# ATmega32C1 device description
Architecture: AVR8; Family: megaAVR
Registers are 8-bit, access not given, no defined reset value unless marked. A register's access mark holds for its fields unless they carry their own. Offsets are from the block's base; [hi:lo] are bit positions; {n}, {i} and the like mark numbered series.

## CPU — CPU Registers
Instances: CPU 0x00
0x39 GPIOR1 — General Purpose IO Register 1
  [7:0] GPIOR (bit 10 of the value upward) — General Purpose IO Register 1 bis
0x3A GPIOR2 — General Purpose IO Register 2
  [7:0] GPIOR (bit 20 of the value upward) — General Purpose IO Register 2 bis
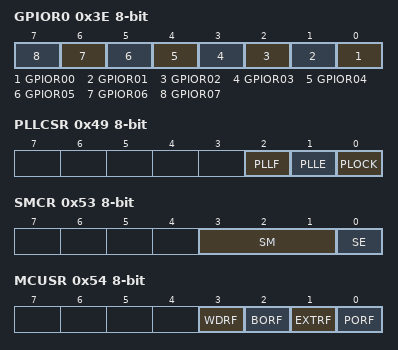
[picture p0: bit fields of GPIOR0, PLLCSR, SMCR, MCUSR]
0x3E GPIOR0 — General Purpose IO Register 0
  [n] GPIOR{n:02} (n=0..7) — General Purpose IO Register 0 bit {n}
0x49 PLLCSR — PLL Control And Status Register
  [2] PLLF — PLL Factor
  [1] PLLE — PLL Enable
  [0] PLOCK — PLL Lock Detector
0x53 SMCR — Sleep Mode Control Register
  [3:1] SM — Sleep Mode Select bits
    0=IDLE; 1=ADC (ADC Noise Reduction (If Available)); 2=PDOWN (Power Down); 6=STDBY (Standby)
  [0] SE — Sleep Enable
0x54 MCUSR — MCU Status Register
  [3] WDRF — Watchdog Reset Flag
  [2] BORF — Brown-out Reset Flag
  [1] EXTRF — External Reset Flag
  [0] PORF — Power-on reset flag
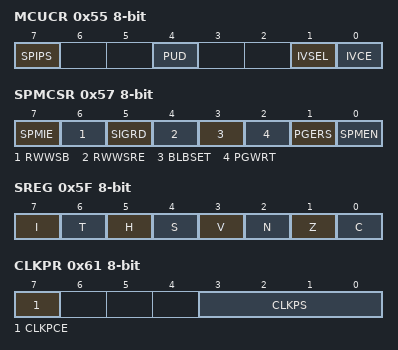
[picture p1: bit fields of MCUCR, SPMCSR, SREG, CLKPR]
0x55 MCUCR — MCU Control Register
  [7] SPIPS — SPI Pin Select
  [4] PUD — Pull-up disable
  [1] IVSEL — Interrupt Vector Select
  [0] IVCE — Interrupt Vector Change Enable
0x57 SPMCSR — Store Program Memory Control Register
  [7] SPMIE — SPM Interrupt Enable
  [6] RWWSB — Read While Write Section Busy
  [5] SIGRD — Signature Row Read
  [4] RWWSRE — Read While Write section read enable
  [3] BLBSET — Boot Lock Bit Set
  [2] PGWRT — Page Write
  [1] PGERS — Page Erase
  [0] SPMEN — Store Program Memory Enable
0x5D SP 16-bit — Stack Pointer
0x5F SREG — Status Register
  [7] I — Global Interrupt Enable
  [6] T — Bit Copy Storage
  [5] H — Half Carry Flag
  [4] S — Sign Bit
  [3] V — Two's Complement Overflow Flag
  [2] N — Negative Flag
  [1] Z — Zero Flag
  [0] C — Carry Flag
0x61 CLKPR
  [7] CLKPCE
  [3:0] CLKPS
    0=1; 1=2; 2=4; 3=8; 4=16; 5=32; 6=64; 7=128; 8=256
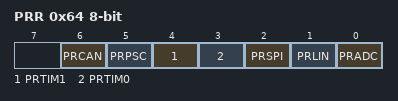
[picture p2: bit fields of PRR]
0x64 PRR — Power Reduction Register
  [6] PRCAN — Power Reduction CAN
  [5] PRPSC — Power Reduction PSC
  [4] PRTIM1 — Power Reduction Timer/Counter1
  [3] PRTIM0 — Power Reduction Timer/Counter0
  [2] PRSPI — Power Reduction Serial Peripheral Interface
  [1] PRLIN — Power Reduction LIN UART
  [0] PRADC — Power Reduction ADC
0x66 OSCCAL — Oscillator Calibration Value
  [7:0] OSCCAL — Oscillator Calibration
Value list OSCCAL_VALUE_ADDRESSES: 0=8_0_MHz

## TC0 (TC8 module) — Timer/Counter, 8-bit
Instances: TC0 0x00
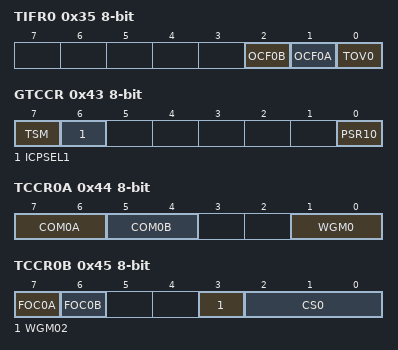
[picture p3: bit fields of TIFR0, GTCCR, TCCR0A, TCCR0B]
0x35 TIFR0 — Timer/Counter0 Interrupt Flag register
  [2] OCF0B — Timer/Counter0 Output Compare Flag 0B
  [1] OCF0A — Timer/Counter0 Output Compare Flag 0A
  [0] TOV0 — Timer/Counter0 Overflow Flag
0x43 GTCCR — General Timer/Counter Control Register
  [7] TSM — Timer/Counter Synchronization Mode
  [6] ICPSEL1 — Timer1 Input Capture Selection Bit
  [0] PSR10 — Prescaler Reset Timer/Counter1 and Timer/Counter0
0x44 TCCR0A — Timer/Counter Control Register A
  [7:6] COM0A — Compare Output Mode, Phase Correct PWM Mode
  [5:4] COM0B — Compare Output Mode, Fast PWm
  [1:0] WGM0 — Waveform Generation Mode
0x45 TCCR0B — Timer/Counter Control Register B
  [7] FOC0A — Force Output Compare A
  [6] FOC0B — Force Output Compare B
  [3] WGM02
  [2:0] CS0 — Clock Select
    0=NO_CLOCK_SOURCE_STOPPED; 1=RUNNING_NO_PRESCALING; 2=RUNNING_CLK_8; 3=RUNNING_CLK_64; 4=RUNNING_CLK_256; 5=RUNNING_CLK_1024; 6=RUNNING_EXTCLK_TN_FALLING_EDGE; 7=RUNNING_EXTCLK_TN_RISING_EDGE
0x46 TCNT0 — Timer/Counter0
  [7:0] TCNT0 — Timer/Counter0 bits
0x47 OCR0A — Timer/Counter0 Output Compare Register
  [7:0] OCR0A — Timer/Counter0 Output Compare bits
0x48 OCR0B — Timer/Counter0 Output Compare Register
  [7:0] OCR0B — Timer/Counter0 Output Compare bits
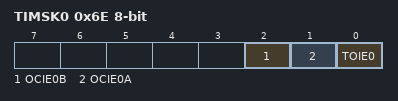
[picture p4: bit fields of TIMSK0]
0x6E TIMSK0 — Timer/Counter0 Interrupt Mask Register
  [2] OCIE0B — Timer/Counter0 Output Compare Match B Interrupt Enable
  [1] OCIE0A — Timer/Counter0 Output Compare Match A Interrupt Enable
  [0] TOIE0 — Timer/Counter0 Overflow Interrupt Enable
